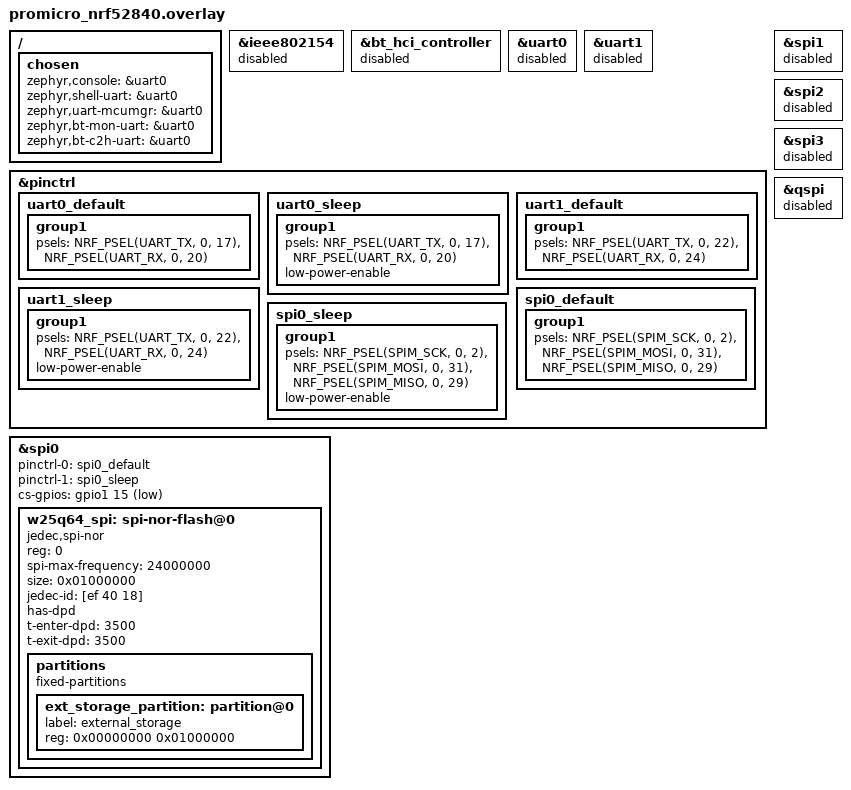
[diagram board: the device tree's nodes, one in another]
// / {
// 	chosen {
// 		zephyr,console = &rtt;
// 		zephyr,shell-uart = &rtt;
// 	};
// };
/ {
	chosen {
		zephyr,console = &uart0;                     /* in zephyr\boards\nordic\nrf52840dk\nrf52840dk_nrf52840.dts:19 */
		zephyr,shell-uart = &uart0;                  /* in zephyr\boards\nordic\nrf52840dk\nrf52840dk_nrf52840.dts:20 */
		zephyr,uart-mcumgr = &uart0;                 /* in zephyr\boards\nordic\nrf52840dk\nrf52840dk_nrf52840.dts:21 */
		zephyr,bt-mon-uart = &uart0;                 /* in zephyr\boards\nordic\nrf52840dk\nrf52840dk_nrf52840.dts:22 */
		zephyr,bt-c2h-uart = &uart0;                 /* in zephyr\boards\nordic\nrf52840dk\nrf52840dk_nrf52840.dts:23 */
	};
};
/delete-node/ &zephyr_udc0;

// &usbd {
// 	status = "disabled";
// };

// &board_cdc_acm_uart {
// 	status = "disabled";
// };

&ieee802154 {
	status = "disabled";
};

&bt_hci_controller {
	status = "disabled";
};

&uart0 {
	status = "disabled";
};

&uart1 {
	status = "disabled";
};

&uart0 {
	status = "disabled";
};

&uart1 {
	status = "disabled";
};

&pinctrl {
	/* --- uart0 Pinctrl --- */
	uart0_default: uart0_default {
		group1 {
			psels = <NRF_PSEL(UART_TX, 0, 17)>,
					<NRF_PSEL(UART_RX, 0, 20)>;
		};
	};

	uart0_sleep: uart0_sleep {
		group1 {
			psels = <NRF_PSEL(UART_TX, 0, 17)>,
					<NRF_PSEL(UART_RX, 0, 20)>;
			low-power-enable;
		};
	};

	/* --- uart1 Pinctrl --- */
	uart1_default: uart1_default {
		group1 {
			psels = <NRF_PSEL(UART_TX, 0, 22)>,
					<NRF_PSEL(UART_RX, 0, 24)>;
		};
	};

	uart1_sleep: uart1_sleep {
		group1 {
			psels = <NRF_PSEL(UART_TX, 0, 22)>,
					<NRF_PSEL(UART_RX, 0, 24)>;
			low-power-enable;
		};
	};

	/* --- spi0 Pinctrl --- */
	spi0_default: spi0_default {
		group1 {
			psels = <NRF_PSEL(SPIM_SCK, 0, 2)>,
					<NRF_PSEL(SPIM_MOSI, 0, 31)>,
					<NRF_PSEL(SPIM_MISO, 0, 29)>;
		};
	};

	spi0_sleep: spi0_sleep {
		group1 {
			psels = <NRF_PSEL(SPIM_SCK, 0, 2)>,
					<NRF_PSEL(SPIM_MOSI, 0, 31)>,
					<NRF_PSEL(SPIM_MISO, 0, 29)>;
			low-power-enable;
		};
	};
};

&spi0 {
	status = "okay";
	pinctrl-0 = <&spi0_default>;
	pinctrl-1 = <&spi0_sleep>;
	pinctrl-names = "default", "sleep";
	cs-gpios = <&gpio1 15 GPIO_ACTIVE_LOW>;

	w25q64_spi: spi-nor-flash@0 {
		compatible = "jedec,spi-nor";
		reg = <0>;
		spi-max-frequency = <24000000>;
		size = <0x01000000>; /* 128 Mbit = 16 MByte */
		status = "okay";
		jedec-id = [ef 40 18];
		has-dpd;
		t-enter-dpd = <3500>;
		t-exit-dpd = <3500>;

		partitions {
			compatible = "fixed-partitions";
			#address-cells = <1>;
			#size-cells = <1>;

			ext_storage_partition: partition@0 {
				label = "external_storage";
				reg = <0x00000000 0x01000000>; /* Full 128 MBit = 16 MByte */
			};
		};
	};
};

&spi1 {
	status = "disabled";
};

&spi2 {
	status = "disabled";
};

&spi3 {
	status = "disabled";
};

&qspi {
	status = "disabled";
};
